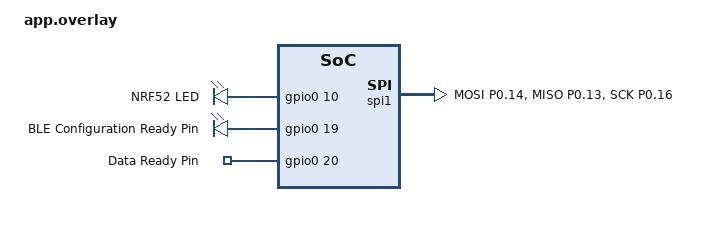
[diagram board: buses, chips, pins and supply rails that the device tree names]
/ {
    aliases {
        led0 = &led_nrf52;
        data-ready = &data_ready_pin;
        ble-cnfg-ready = &ble_cnfg_ready_pin;
    };

    chosen {
        nordic,nus-uart = &uart0;
    };

    leds {
        compatible = "gpio-leds";
        led_nrf52: led_nrf52 {
            gpios = <&gpio0 10 GPIO_ACTIVE_HIGH>;
            label = "NRF52 LED";
        };

        ble_cnfg_ready_pin: ble_cnfg_ready_pin {
            gpios = <&gpio0 19 GPIO_ACTIVE_HIGH>;
            label = "BLE Configuration Ready Pin";
        };
    };

    buttons {
        compatible = "gpio-keys";
        data_ready_pin: data_ready_pin {
            gpios = <&gpio0 20 (GPIO_ACTIVE_HIGH | GPIO_PULL_DOWN)>;
            label = "Data Ready Pin";
        };
    };
};

&pinctrl {
    spi_master_default: spi_master_default {
        group1 {
            psels = <NRF_PSEL(SPIM_MOSI, 0, 14)>,
                    <NRF_PSEL(SPIM_MISO, 0, 13)>,
                    <NRF_PSEL(SPIM_SCK, 0, 16)>;
        };
    };

    spi_master_sleep: spi_master_sleep {
        group1 {
            psels = <NRF_PSEL(SPIM_MOSI, 0, 14)>,
                    <NRF_PSEL(SPIM_MISO, 0, 13)>,
                    <NRF_PSEL(SPIM_SCK, 0, 16)>;
            low-power-enable;
        };
    };
};

&spi1 {
    status = "okay";
    compatible = "nordic,nrf-spim";
    pinctrl-0 = <&spi_master_default>;
    pinctrl-1 = <&spi_master_sleep>;
    pinctrl-names = "default", "sleep";
};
